# va416xx register map
Vendor: VORAGO TECHNOLOGIES; Series: M4; File version: 1.3
CPU: CM4 r0p1, little endian, no MPU, FPU, 4 interrupt priority bits
Registers are 32-bit, read-write, reset 0x0 unless marked. A register's access mark holds for its fields unless they carry their own. Offsets are from the block's base; [hi:lo] are bit positions.

## SPW — SpaceWire Peripheral
Base 0x40003000
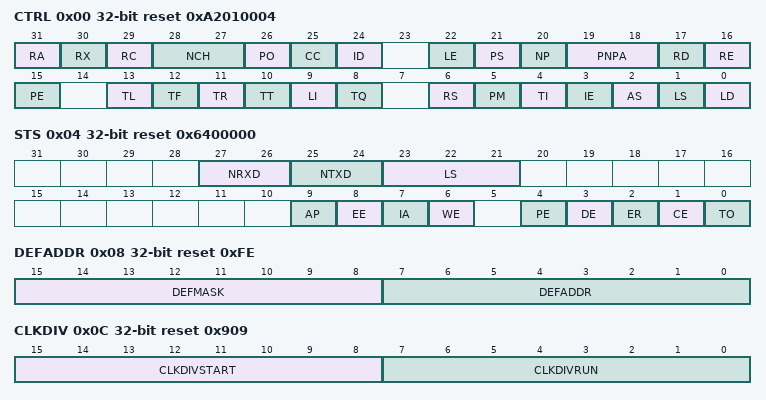
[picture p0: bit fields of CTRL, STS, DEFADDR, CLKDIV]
0x00 CTRL reset 0xA2010004 — Control Register
  [31] RA ro — Reads as 1 if the RMAP command handler is available
  [30] RX ro — Reads as 1 if unaligned writes are available for the receiver
  [29] RC ro — Reads as 1 if RMAP CRC is enabled in the core
  [28:27] NCH ro — Number of DMA Channels minus one
  [26] PO ro — The number of available SpaceWire ports minus one
  [25] CC ro — CCSDS/CCITT CRC-16
  [24] ID ro — Interrupt distribution available
  [22] LE — Loop-back Enable
  [21] PS — Selects the active port when the no port force bit is zero
  [20] NP — Disable port force
  [19:18] PNPA ro — SpW Plug-and-Play Available
  [17] RD — If set only one RMAP buffer is used
  [16] RE — Enable RMAP command handler
  [15] PE — SpW Plug-and-Play Enable
  [13] TL — Transmitter Enable Lock Control
  [12] TF — Time-code Flag Filter
  [11] TR — Enable time-code receptions
  [10] TT — Enable time-code transmissions
  [9] LI — Generate interrupt when link error occurs
  [8] TQ — Generate interrupt when a valid time-code is received
  [6] RS — Make complete reset of the SpaceWire node. Self-clearing
  [5] PM — Enable Promiscuous mode
  [4] TI — The host can generate a tick by writing a one to this field
  [3] IE — If set, an interrupt is generated when one or both of bit 8 to 9 is set and its corresponding event occurs
  [2] AS — Automatically start the link when a NULL has been received
  [1] LS — Start the link
  [0] LD — Disable the SpaceWire CODEC
0x04 STS reset 0x6400000 — Status/Interrupt Source Register
  [27:26] NRXD — Number of Receive Descriptors
  [25:24] NTXD — Number of Transmit Descriptors
  [23:21] LS — Link State
  [9] AP — Active port
  [8] EE — Set to one when a packet is received with an EOP after the first byte for a non-RMAP packet and after the second byte for a RMAP packet
  [7] IA — Packet is received with an invalid destination address field
  [6] WE — A synchronization problem has occurred when receiving NChars
  [4] PE — Parity error has occurred
  [3] DE — Disconnection error has occurred
  [2] ER — Escape error has occurred
  [1] CE — Credit has occurred
  [0] TO — A new time count value was received
0x08 DEFADDR reset 0xFE — Node Address Register
  [15:8] DEFMASK — 8-bit default mask used for node identification on the SpaceWire network
  [7:0] DEFADDR — 8-bit node address used for node identification on the SpaceWire network
0x0C CLKDIV reset 0x909 — Clock Divisor Register
  [15:8] CLKDIVSTART — 8-bit Clock divisor value used for the clock-divider during startup
  [7:0] CLKDIVRUN — 8-bit Clock divisor value used for the clock-divider when the link-interface is in the run-state
0x10 DKEY — Destination Key
  [7:0] DESTKEY — RMAP destination key
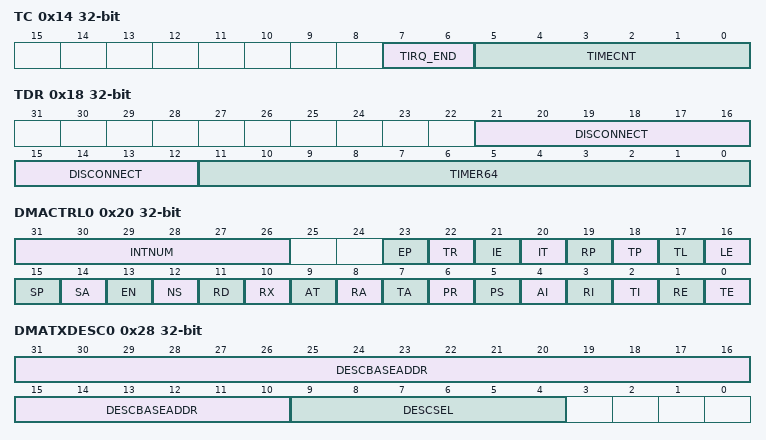
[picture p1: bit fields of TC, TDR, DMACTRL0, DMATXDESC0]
0x14 TC — Time Code Register
  [7:6] TIRQ_END — The current value of the time control flags
  [5:0] TIMECNT — The current value of the system time counter
0x18 TDR ro — Timer and Disconnect Register
  [21:12] DISCONNECT — Used to generate the 850 ns disconnect time period
  [11:0] TIMER64 — Used to generate the 6.4 and 12.8 us time periods
0x20 DMACTRL0 — DMA Control Register
  [31:26] INTNUM — Interrupt number used for this channel
  [23] EP — EEP Termination
  [22] TR — Truncated
  [21] IE — Interrupt code transmit enable on EEP
  [20] IT — Interrupt code transmit enable on truncation
  [19] RP — Receive Packet IRQ
  [18] TP — Transmit Packet IRQ
  [17] TL — Transmit Enable Lock
  [16] LE — Disable transmitter when a link error occurs
  [15] SP — Strip PID
  [14] SA — Strip Address
  [13] EN — Enable Address
  [12] NS — If cleared, packets will be discarded when a packet is arriving and there are no active descriptors. If set, the GRSPW will wait for a descriptor to be activated
  [11] RD — Indicates to the GRSPW that there are enabled descriptors in the descriptor table
  [10] RX ro — Reception to the DMA channel is currently active
  [9] AT ro — Abort the currently transmitting packet and disable transmissions
  [8] RA — An error response was detected on the AHB bus - DMA receive
  [7] TA — An error response was detected on the AHB bus - DMA transmit
  [6] PR — Set each time a packet has been received
  [5] PS — Set each time a packet has been sent
  [4] AI — An interrupt will be generated each time an AHB error occurs when this DMA channel is accessing the bus
  [3] RI — An interrupt will be generated each time a packet has been received
  [2] TI — An interrupt will be generated each time a packet is transmitted
  [1] RE — Packets are allowed to be received to this channel
  [0] TE — Write a one to this bit each time new descriptors are activated in the table
0x24 DMAMAXLEN0 — DMA RX Maximum Length Register
  [24:2] RXMAXLEN — Receiver packet maximum length in bytes
0x28 DMATXDESC0 — DMA Transmitter Descriptor Table Address Register
  [31:10] DESCBASEADDR — Sets the base address of the descriptor table
  [9:4] DESCSEL — Offset into the descriptor table
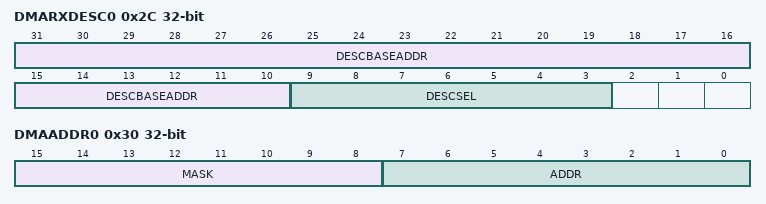
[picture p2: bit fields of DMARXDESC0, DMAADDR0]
0x2C DMARXDESC0 — DMA Receiver Table Destination Register
  [31:10] DESCBASEADDR — Sets the base address of the descriptor table
  [9:3] DESCSEL — Offset into the descriptor table
0x30 DMAADDR0 — DMA Receiver Table Address Register
  [15:8] MASK
  [7:0] ADDR — Address
